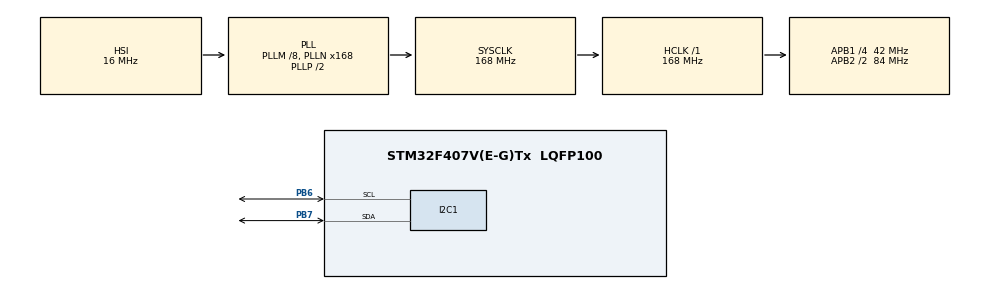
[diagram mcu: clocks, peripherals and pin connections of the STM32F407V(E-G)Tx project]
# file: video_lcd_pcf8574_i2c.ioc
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Mcu.Family=STM32F4
Mcu.Name=STM32F407V(E-G)Tx
Mcu.Package=LQFP100
NVIC.PriorityGroup=NVIC_PRIORITYGROUP_4
PB6.Mode=I2C
PB6.Signal=I2C1_SCL
PB7.Mode=I2C
PB7.Signal=I2C1_SDA
PH0-OSC_IN.Mode=HSE-External-Oscillator
PH0-OSC_IN.Signal=RCC_OSC_IN
PH1-OSC_OUT.Mode=HSE-External-Oscillator
PH1-OSC_OUT.Signal=RCC_OSC_OUT
ProjectManager.HeapSize=0x200
ProjectManager.StackSize=0x400
ProjectManager.TargetToolchain=MDK-ARM V5
RCC.48MHZClocksFreq_Value=84000000
RCC.AHBFreq_Value=168000000
RCC.APB1CLKDivider=RCC_HCLK_DIV4
RCC.APB1Freq_Value=42000000
RCC.APB1TimFreq_Value=84000000
RCC.APB2CLKDivider=RCC_HCLK_DIV2
RCC.APB2Freq_Value=84000000
RCC.APB2TimFreq_Value=168000000
RCC.CortexFreq_Value=168000000
RCC.HCLKFreq_Value=168000000
RCC.HSE_VALUE=8000000
RCC.HSI_VALUE=16000000
RCC.LSE_VALUE=32768
RCC.PLLM=8
RCC.PLLN=168
RCC.SYSCLKFreq_VALUE=168000000
RCC.SYSCLKSource=RCC_SYSCLKSOURCE_PLLCLK
RCC.VCOOutputFreq_Value=336000000
board=video_lcd_pcf8574_i2c

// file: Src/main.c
/**
  ******************************************************************************
  * File Name          : main.c
  * Description        : Main program body
  ******************************************************************************
  ** This notice applies to any and all portions of this file
  * that are not between comment pairs USER CODE BEGIN and
  * USER CODE END. Other portions of this file, whether
  * inserted by the user or by software development tools
  * are owned by their respective copyright owners.
  *
  * COPYRIGHT(c) 2018 STMicroelectronics
  *
  * Redistribution and use in source and binary forms, with or without modification,
  * are permitted provided that the following conditions are met:
  *   1. Redistributions of source code must retain the above copyright notice,
  *      this list of conditions and the following disclaimer.
  *   2. Redistributions in binary form must reproduce the above copyright notice,
  *      this list of conditions and the following disclaimer in the documentation
  *      and/or other materials provided with the distribution.
  *   3. Neither the name of STMicroelectronics nor the names of its contributors
  *      may be used to endorse or promote products derived from this software
  *      without specific prior written permission.
  *
  * THIS SOFTWARE IS PROVIDED BY THE COPYRIGHT HOLDERS AND CONTRIBUTORS "AS IS"
  * AND ANY EXPRESS OR IMPLIED WARRANTIES, INCLUDING, BUT NOT LIMITED TO, THE
  * IMPLIED WARRANTIES OF MERCHANTABILITY AND FITNESS FOR A PARTICULAR PURPOSE ARE
  * DISCLAIMED. IN NO EVENT SHALL THE COPYRIGHT HOLDER OR CONTRIBUTORS BE LIABLE
  * FOR ANY DIRECT, INDIRECT, INCIDENTAL, SPECIAL, EXEMPLARY, OR CONSEQUENTIAL
  * DAMAGES (INCLUDING, BUT NOT LIMITED TO, PROCUREMENT OF SUBSTITUTE GOODS OR
  * SERVICES; LOSS OF USE, DATA, OR PROFITS; OR BUSINESS INTERRUPTION) HOWEVER
  * CAUSED AND ON ANY THEORY OF LIABILITY, WHETHER IN CONTRACT, STRICT LIABILITY,
  * OR TORT (INCLUDING NEGLIGENCE OR OTHERWISE) ARISING IN ANY WAY OUT OF THE USE
  * OF THIS SOFTWARE, EVEN IF ADVISED OF THE POSSIBILITY OF SUCH DAMAGE.
  *
  ******************************************************************************
  */
#include "main.h"
#include "stm32f4xx_hal.h"

/* USER CODE BEGIN Includes */
#include "lcd_i2cModule.h" // lcd kütüphanesi eklendi...
/* USER CODE END Includes */

I2C_HandleTypeDef hi2c1;

/* USER CODE BEGIN PV */
/* Private variables ---------------------------------------------------------*/

/* USER CODE END PV */

void SystemClock_Config(void);
static void MX_GPIO_Init(void);
static void MX_I2C1_Init(void);

/* USER CODE BEGIN PFP */
/* Private function prototypes -----------------------------------------------*/

/* USER CODE END PFP */

int main(void)
{

  /* MCU Configuration----------------------------------------------------------*/

  /* Reset of all peripherals, Initializes the Flash interface and the Systick. */
  HAL_Init();

  /* Configure the system clock */
  SystemClock_Config();

  /* Initialize all configured peripherals */
  MX_GPIO_Init();
  MX_I2C1_Init();

  /* USER CODE BEGIN 2 */
  LCD_i2cDeviceCheck();
	LCD_Init();
	LCD_BackLight(LCD_BL_ON);
	LCD_SetCursor(1,1);
  /* USER CODE END 2 */
/*-----------------------example 4------------------------- */
uint8_t L= 0x4C;   // karakter L= upper bits:0100 , lower bits:1100
uint8_t C= 0x43;  // karakter L= upper bits:0100 , lower bits:0011
uint8_t D= 0x44;   // karakter L= upper bits:0100 , lower bits:0100
uint8_t Symbol= 0x23;  // karakter L= upper bits:0010 , lower bits:0011
// bu da benden lcd character set: *= upper bits:0010 , lower bits:1010
// https://mil.ufl.edu/3744/docs/lcdmanual/characterset.html
uint8_t yildiz=0x2A;

LCD_SetCursor(1,1); // delete this it has already written above
LCD_Write_Data(Symbol);
LCD_Write_Data(L);
LCD_Write_Data(C);
LCD_Write_Data(D);
LCD_Write_Data(yildiz);
LCD_Set_Command(LCD_DISPLAY_CONTROL|DISPLAY_ON|CURSOR_ON|BLINK_ON);

  /* Infinite loop */
  while (1)
  {
		// asagida bi kaç uygulama örgegi ekleycegiz örnekler veysel gökdemirden :

		//		/*--------------------Example 1---------------- */
		// ekrana float ve int degerlerini bastirdik
		//		int current =10; // integer value
		//		float volt=2.77; // float value
		//		LCD_SetCursor(1,1);   // 1. satir 1. sutun
		//		LCD_Print("volt:%.2f V ",volt); // float degerini ekrana basalim
		//		LCD_SetCursor(2,1); //2. satir 1.sütun
		//		LCD_Print("current:%.0f A",(float)current);
		//		HAL_Delay(2000);
		//		LCD_Clear();
		//		HAL_Delay(20);
		/* -----------------------------------------------*/

		/*--------------------Example 2---------------- */
		// kayma olmadan tüm string i ekranda gösterdi tüm metni 2 sütunda gösterdi.
//		LCD_Send_String("string example str no slide",STR_NOSLIDE);
//		// example of sending string value
//		HAL_Delay(800);
//		LCD_Clear();
//		HAL_Delay(20);
		/*-----------------------------------------------*/

		//------------------------example 3-----------------------//
//		// yazilan string'i lcd'din en son sutünun dan baslatiyor kayarak yazdiriyor...
//		LCD_SetCursor(1,1); // 1. satir 1. sutun
//		LCD_Send_String("1.line slide example",STR_SLIDE);
//		LCD_SetCursor(2,1); //2. satir 1.sütun
//		LCD_Send_String("2.line slide example",STR_SLIDE);
//		HAL_Delay(2000);
//		LCD_Clear();
//		HAL_Delay(20);
//
		/*---------------------------------------------------------*/

  }

}

/** System Clock Configuration
*/
void SystemClock_Config(void)
{

  RCC_OscInitTypeDef RCC_OscInitStruct;
  RCC_ClkInitTypeDef RCC_ClkInitStruct;

    /**Configure the main internal regulator output voltage
    */
  __HAL_RCC_PWR_CLK_ENABLE();

  __HAL_PWR_VOLTAGESCALING_CONFIG(PWR_REGULATOR_VOLTAGE_SCALE1);

    /**Initializes the CPU, AHB and APB busses clocks
    */
  RCC_OscInitStruct.OscillatorType = RCC_OSCILLATORTYPE_HSI;
  RCC_OscInitStruct.HSIState = RCC_HSI_ON;
  RCC_OscInitStruct.HSICalibrationValue = 16;
  RCC_OscInitStruct.PLL.PLLState = RCC_PLL_ON;
  RCC_OscInitStruct.PLL.PLLSource = RCC_PLLSOURCE_HSI;
  RCC_OscInitStruct.PLL.PLLM = 8;
  RCC_OscInitStruct.PLL.PLLN = 168;
  RCC_OscInitStruct.PLL.PLLP = RCC_PLLP_DIV2;
  RCC_OscInitStruct.PLL.PLLQ = 4;
  if (HAL_RCC_OscConfig(&RCC_OscInitStruct) != HAL_OK)
  {
    _Error_Handler(__FILE__, __LINE__);
  }

    /**Initializes the CPU, AHB and APB busses clocks
    */
  RCC_ClkInitStruct.ClockType = RCC_CLOCKTYPE_HCLK|RCC_CLOCKTYPE_SYSCLK
                              |RCC_CLOCKTYPE_PCLK1|RCC_CLOCKTYPE_PCLK2;
  RCC_ClkInitStruct.SYSCLKSource = RCC_SYSCLKSOURCE_PLLCLK;
  RCC_ClkInitStruct.AHBCLKDivider = RCC_SYSCLK_DIV1;
  RCC_ClkInitStruct.APB1CLKDivider = RCC_HCLK_DIV4;
  RCC_ClkInitStruct.APB2CLKDivider = RCC_HCLK_DIV2;

  if (HAL_RCC_ClockConfig(&RCC_ClkInitStruct, FLASH_LATENCY_5) != HAL_OK)
  {
    _Error_Handler(__FILE__, __LINE__);
  }

    /**Configure the Systick interrupt time
    */
  HAL_SYSTICK_Config(HAL_RCC_GetHCLKFreq()/1000);

    /**Configure the Systick
    */
  HAL_SYSTICK_CLKSourceConfig(SYSTICK_CLKSOURCE_HCLK);

  /* SysTick_IRQn interrupt configuration */
  HAL_NVIC_SetPriority(SysTick_IRQn, 0, 0);
}

/* I2C1 init function */
static void MX_I2C1_Init(void)
{

  hi2c1.Instance = I2C1;
  hi2c1.Init.ClockSpeed = 100000;
  hi2c1.Init.DutyCycle = I2C_DUTYCYCLE_2;
  hi2c1.Init.OwnAddress1 = 0;
  hi2c1.Init.AddressingMode = I2C_ADDRESSINGMODE_7BIT;
  hi2c1.Init.DualAddressMode = I2C_DUALADDRESS_DISABLE;
  hi2c1.Init.OwnAddress2 = 0;
  hi2c1.Init.GeneralCallMode = I2C_GENERALCALL_DISABLE;
  hi2c1.Init.NoStretchMode = I2C_NOSTRETCH_DISABLE;
  if (HAL_I2C_Init(&hi2c1) != HAL_OK)
  {
    _Error_Handler(__FILE__, __LINE__);
  }

}

/** Configure pins as
        * Analog
        * Input
        * Output
        * EVENT_OUT
        * EXTI
*/
static void MX_GPIO_Init(void)
{

  /* GPIO Ports Clock Enable */
  __HAL_RCC_GPIOH_CLK_ENABLE();
  __HAL_RCC_GPIOB_CLK_ENABLE();

}

void _Error_Handler(char * file, int line)
{
  while(1)
  {
  }
}

/************************ (C) COPYRIGHT STMicroelectronics *****END OF FILE****/
